# M3HN register map
File version: 0.1
Registers are 32-bit, read-write, reset 0x0 unless marked. A register's access mark holds for its fields unless they carry their own. Offsets are from the block's base; [hi:lo] are bit positions; {n}, {i} and the like mark numbered series.

## PF — Port F
Base 0x400C0500
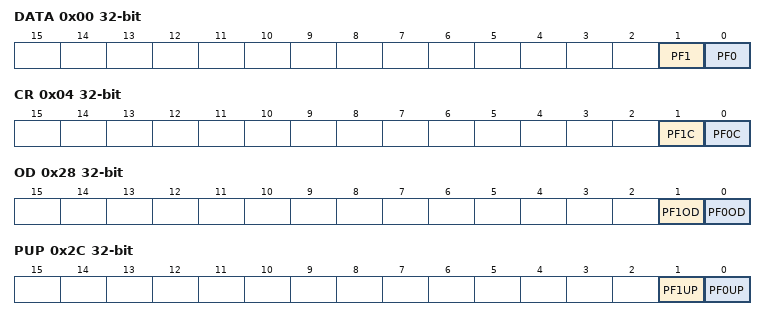
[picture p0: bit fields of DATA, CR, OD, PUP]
0x00 DATA — PF Data Register
  [1] PF1, [0] PF0
0x04 CR — PF Control Register
  [1] PF1C, [0] PF0C
0x28 OD — PF Open Drain Control Register
  [1] PF1OD, [0] PF0OD
0x2C PUP — PF Pull-up Control Register
  [1] PF1UP, [0] PF0UP
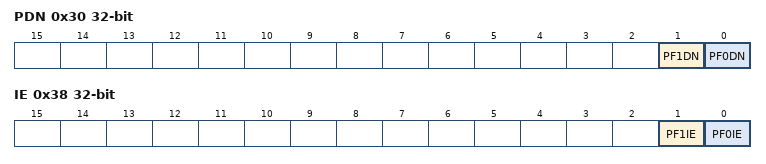
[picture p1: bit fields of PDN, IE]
0x30 PDN — PF Pull-Down Control Register
  [1] PF1DN, [0] PF0DN
0x38 IE — PF Input Enable Control Register
  [1] PF1IE, [0] PF0IE

## PG — Port G
Base 0x400C0600
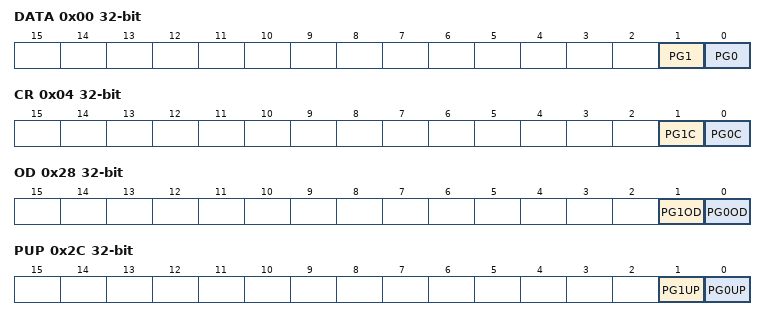
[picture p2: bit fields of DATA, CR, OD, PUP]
0x00 DATA — PG Data Register
  [1] PG1, [0] PG0
0x04 CR — PG Control Register
  [1] PG1C, [0] PG0C
0x28 OD — PG Open Drain Control Register
  [1] PG1OD, [0] PG0OD
0x2C PUP — PG Pull-up Control Register
  [1] PG1UP, [0] PG0UP
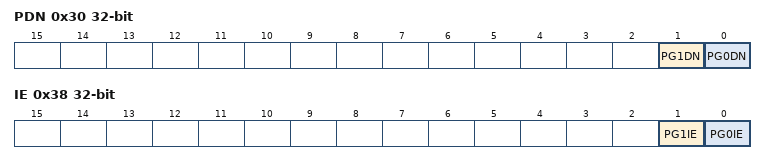
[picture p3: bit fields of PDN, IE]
0x30 PDN — PG Pull-Down Control Register
  [1] PG1DN, [0] PG0DN
0x38 IE — PG Input Enable Control Register
  [1] PG1IE, [0] PG0IE

## PH — Port H
Base 0x400C0700
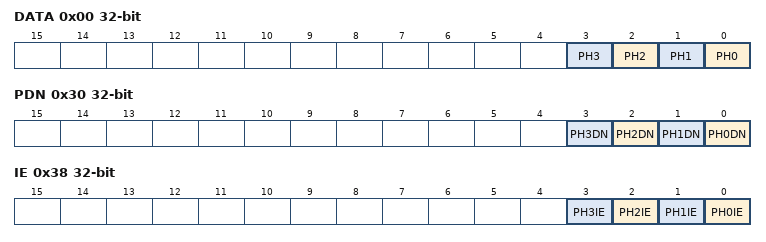
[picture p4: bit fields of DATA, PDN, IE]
0x00 DATA — PH Data Register
  [n] PH{n} (n=0..3)
0x30 PDN — PH Pull-Down Control Register
  [n] PH{n}DN (n=0..3)
0x38 IE — PH Input Enable Control Register
  [n] PH{n}IE (n=0..3)

## PJ — Port J
Base 0x400C0800
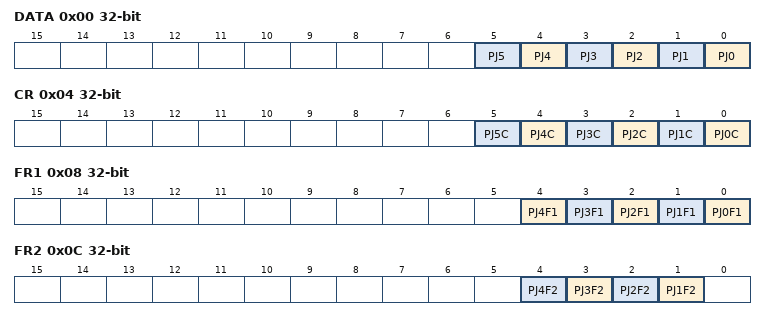
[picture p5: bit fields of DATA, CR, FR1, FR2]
0x00 DATA — PJ Data Register
  [n] PJ{n} (n=0..5)
0x04 CR — PJ Control Register
  [n] PJ{n}C (n=0..5)
0x08 FR1 — PJ Function Register 1
  [n] PJ{n}F1 (n=0..4)
0x0C FR2 — PJ Function Register 2
  [n] PJ{n}F2 (n=1..4)
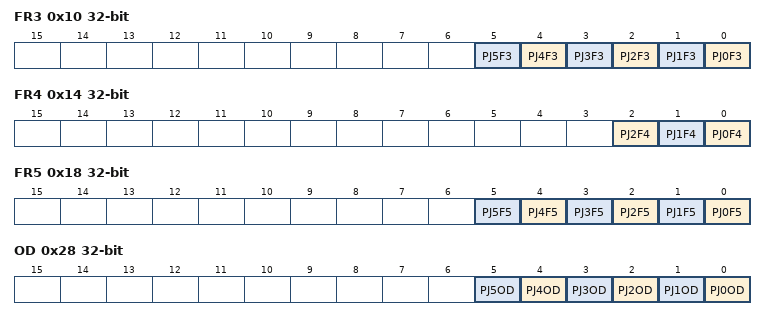
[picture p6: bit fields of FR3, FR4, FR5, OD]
0x10 FR3 — PJ Function Register 3
  [n] PJ{n}F3 (n=0..5)
0x14 FR4 — PJ Function Register 4
  [2] PJ2F4, [1] PJ1F4, [0] PJ0F4
0x18 FR5 — PJ Function Register 5
  [n] PJ{n}F5 (n=0..5)
0x28 OD — PJ Open Drain Control Register
  [n] PJ{n}OD (n=0..5)
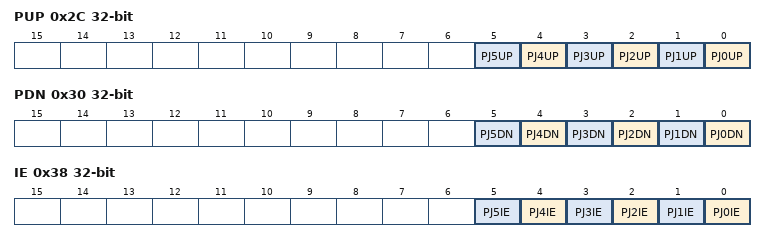
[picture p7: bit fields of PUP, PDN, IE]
0x2C PUP — PJ Pull-up Control Register
  [n] PJ{n}UP (n=0..5)
0x30 PDN — PJ Pull-Down Control Register
  [n] PJ{n}DN (n=0..5)
0x38 IE — PJ Input Enable Control Register
  [n] PJ{n}IE (n=0..5)

## PK — Port K
Base 0x400C0900
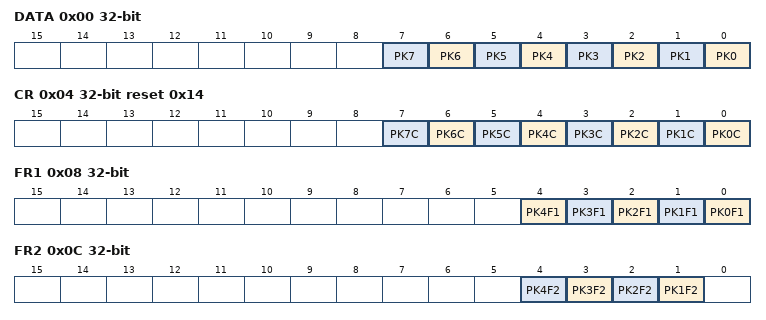
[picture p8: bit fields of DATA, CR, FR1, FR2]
0x00 DATA — PK Data Register
  [n] PK{n} (n=0..7)
0x04 CR reset 0x14 — PK Control Register
  [n] PK{n}C (n=0..7)
0x08 FR1 — PK Function Register 1
  [n] PK{n}F1 (n=0..4)
0x0C FR2 — PK Function Register 2
  [n] PK{n}F2 (n=1..4)
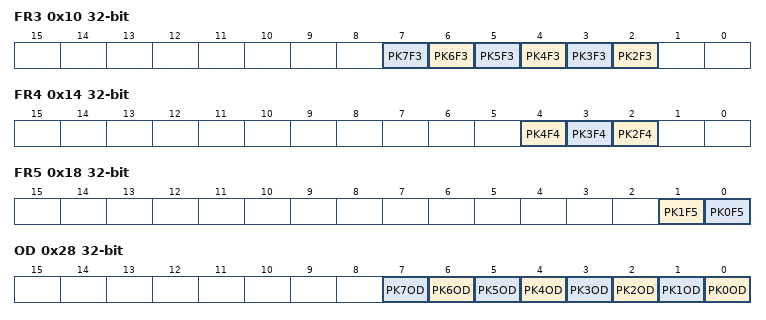
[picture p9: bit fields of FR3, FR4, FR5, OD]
0x10 FR3 — PK Function Register 3
  [n] PK{n}F3 (n=2..7)
0x14 FR4 — PK Function Register 4
  [4] PK4F4, [3] PK3F4, [2] PK2F4
0x18 FR5 — PK Function Register 5
  [1] PK1F5, [0] PK0F5
0x28 OD — PK Open Drain Control Register
  [n] PK{n}OD (n=0..7)
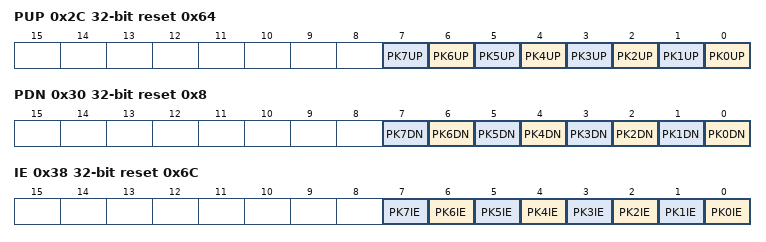
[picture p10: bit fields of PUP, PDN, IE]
0x2C PUP reset 0x64 — PK Pull-up Control Register
  [n] PK{n}UP (n=0..7)
0x30 PDN reset 0x8 — PK Pull-Down Control Register
  [n] PK{n}DN (n=0..7)
0x38 IE reset 0x6C — PK Input Enable Control Register
  [n] PK{n}IE (n=0..7)

## PL — Port L
Base 0x400C0A00
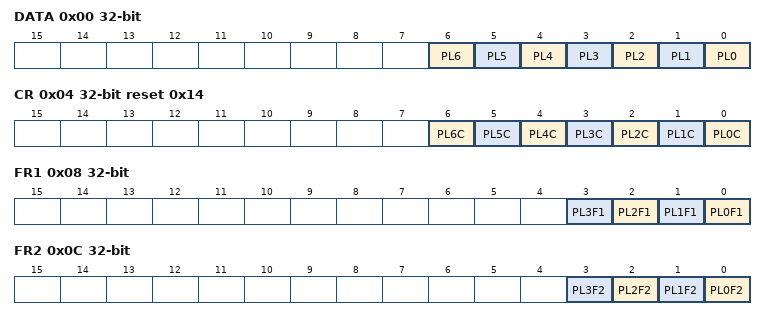
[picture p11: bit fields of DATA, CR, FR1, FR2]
0x00 DATA — PL Data Register
  [n] PL{n} (n=0..6)
0x04 CR reset 0x14 — PL Control Register
  [n] PL{n}C (n=0..6)
0x08 FR1 — PL Function Register 1
  [n] PL{n}F1 (n=0..3)
0x0C FR2 — PL Function Register 2
  [n] PL{n}F2 (n=0..3)
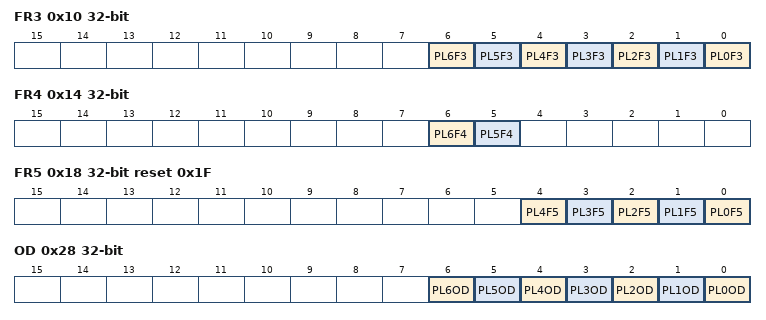
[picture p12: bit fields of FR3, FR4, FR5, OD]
0x10 FR3 — PL Function Register 3
  [n] PL{n}F3 (n=0..6)
0x14 FR4 — PL Function Register 4
  [6] PL6F4, [5] PL5F4
0x18 FR5 reset 0x1F — PL Function Register 4
  [n] PL{n}F5 (n=0..4)
0x28 OD — PL Open Drain Control Register
  [n] PL{n}OD (n=0..6)
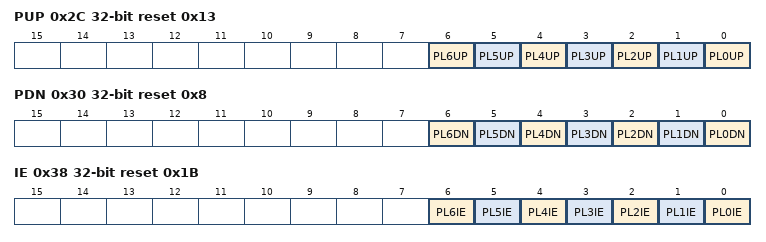
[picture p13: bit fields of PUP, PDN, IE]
0x2C PUP reset 0x13 — PL Pull-up Control Register
  [n] PL{n}UP (n=0..6)
0x30 PDN reset 0x8 — PL Pull-Down Control Register
  [n] PL{n}DN (n=0..6)
0x38 IE reset 0x1B — PL Input Enable Control Register
  [n] PL{n}IE (n=0..6)

## PM — Port M
Base 0x400C0B00
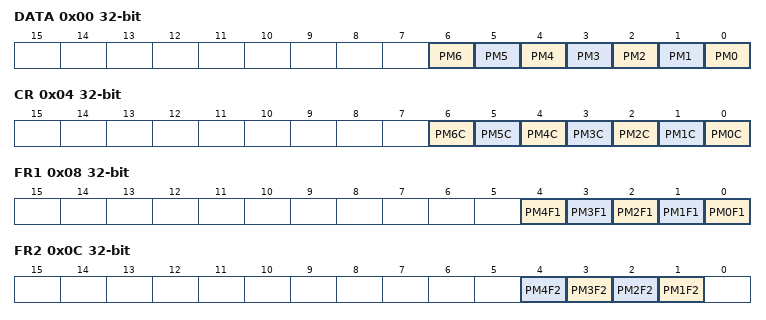
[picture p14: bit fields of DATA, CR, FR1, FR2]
0x00 DATA — PM Data Register
  [n] PM{n} (n=0..6)
0x04 CR — PM Control Register
  [n] PM{n}C (n=0..6)
0x08 FR1 — PM Function Register 1
  [n] PM{n}F1 (n=0..4)
0x0C FR2 — PM Function Register 2
  [n] PM{n}F2 (n=1..4)
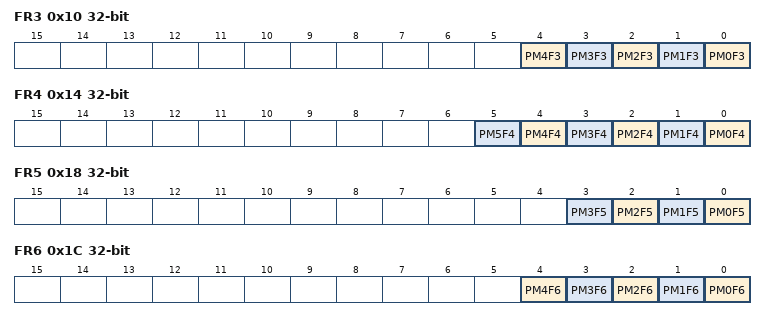
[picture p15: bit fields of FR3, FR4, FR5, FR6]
0x10 FR3 — PM Function Register 3
  [n] PM{n}F3 (n=0..4)
0x14 FR4 — PM Function Register 4
  [n] PM{n}F4 (n=0..5)
0x18 FR5 — PM Function Register 5
  [n] PM{n}F5 (n=0..3)
0x1C FR6 — PM Function Register 6
  [n] PM{n}F6 (n=0..4)
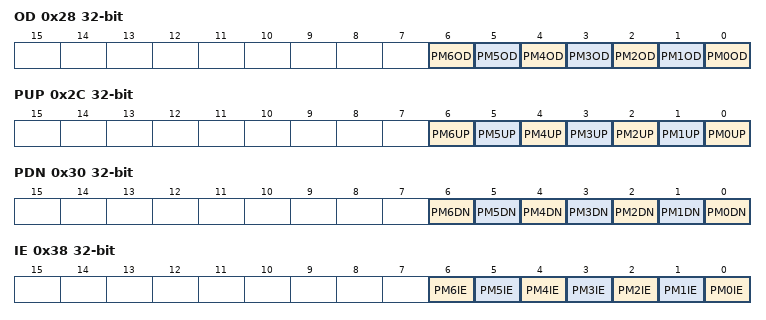
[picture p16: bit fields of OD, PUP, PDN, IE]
0x28 OD — PM Open Drain Control Register
  [n] PM{n}OD (n=0..6)
0x2C PUP — PM Pull-up Control Register
  [n] PM{n}UP (n=0..6)
0x30 PDN — PM Pull-Down Control Register
  [n] PM{n}DN (n=0..6)
0x38 IE — PM Input Enable Control Register
  [n] PM{n}IE (n=0..6)
